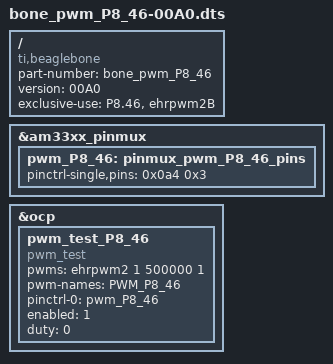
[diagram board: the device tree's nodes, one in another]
/*
 * Copyright (C) 2013 CircuitCo
 * Copyright (C) 2013 Texas Instruments
 *
 * This program is free software; you can redistribute it and/or modify
 * it under the terms of the GNU General Public License version 2 as
 * published by the Free Software Foundation.
 */
/dts-v1/;
/plugin/;

/ {
	compatible = "ti,beaglebone", "ti,beaglebone-black", "ti,beaglebone-green";

	/* identification */
	part-number = "bone_pwm_P8_46";
	version = "00A0";

	/* state the resources this cape uses */
	exclusive-use =
		/* the pin header uses */
		"P8.46",		/* pwm: ehrpwm2B */
		/* the hardware IP uses */
		"ehrpwm2B";

	fragment@0 {
		target = <&am33xx_pinmux>;
		__overlay__ {
			pwm_P8_46: pinmux_pwm_P8_46_pins {
				pinctrl-single,pins = <0x0a4  0x3>; /* P8_46 (ZCZ ball R2) | MODE 3 */
			};
		};
	};

	fragment@1 {
		target = <&ocp>;
		__overlay__ {
			pwm_test_P8_46 {
				compatible	= "pwm_test";
				pwms 		= <&ehrpwm2 1 500000 1>;
				pwm-names 	= "PWM_P8_46";
			    pinctrl-names	= "default";
			    pinctrl-0	= <&pwm_P8_46>;
				enabled		= <1>;
				duty		= <0>;
				status 		= "okay";
			};
		};
	};
};
